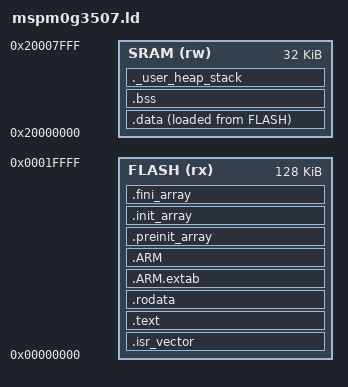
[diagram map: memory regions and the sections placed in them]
/**
 * @file    mspm0g3507.ld
 * @brief   MSPM0G3507链接脚本
 * @version 1.0
 * @date    2024-12-19
 * @author  Bob (架构师)
 * 
 * @note    适用于MSPM0G3507微控制器的链接脚本
 *          Flash: 128KB, SRAM: 32KB
 */

/* 内存布局定义 */
MEMORY
{
    FLASH (rx)  : ORIGIN = 0x00000000, LENGTH = 128K
    SRAM (rw)   : ORIGIN = 0x20000000, LENGTH = 32K
}

/* 栈大小定义 */
_stack_size = 0x1000;  /* 4KB栈空间 */
_heap_size = 0x1000;   /* 4KB堆空间 */

/* 栈顶地址定义 */
_estack = ORIGIN(SRAM) + LENGTH(SRAM);

/* 入口点 */
ENTRY(Reset_Handler)

/* 段定义 */
SECTIONS
{
    /* 中断向量表 */
    .isr_vector :
    {
        . = ALIGN(4);
        KEEP(*(.isr_vector))
        . = ALIGN(4);
    } > FLASH

    /* 程序代码段 */
    .text :
    {
        . = ALIGN(4);
        *(.text)
        *(.text*)
        *(.glue_7)
        *(.glue_7t)
        *(.eh_frame)
        
        KEEP (*(.init))
        KEEP (*(.fini))
        
        . = ALIGN(4);
        _etext = .;
    } > FLASH

    /* 只读数据段 */
    .rodata :
    {
        . = ALIGN(4);
        *(.rodata)
        *(.rodata*)
        . = ALIGN(4);
    } > FLASH

    /* ARM异常处理索引 */
    .ARM.extab :
    {
        *(.ARM.extab* .gnu.linkonce.armextab.*)
    } > FLASH
    
    .ARM :
    {
        __exidx_start = .;
        *(.ARM.exidx*)
        __exidx_end = .;
    } > FLASH

    /* 预初始化数组 */
    .preinit_array :
    {
        PROVIDE_HIDDEN (__preinit_array_start = .);
        KEEP (*(.preinit_array*))
        PROVIDE_HIDDEN (__preinit_array_end = .);
    } > FLASH

    /* 初始化数组 */
    .init_array :
    {
        PROVIDE_HIDDEN (__init_array_start = .);
        KEEP (*(SORT(.init_array.*)))
        KEEP (*(.init_array*))
        PROVIDE_HIDDEN (__init_array_end = .);
    } > FLASH

    /* 析构数组 */
    .fini_array :
    {
        PROVIDE_HIDDEN (__fini_array_start = .);
        KEEP (*(SORT(.fini_array.*)))
        KEEP (*(.fini_array*))
        PROVIDE_HIDDEN (__fini_array_end = .);
    } > FLASH

    /* 初始化数据段 */
    _sidata = LOADADDR(.data);
    .data :
    {
        . = ALIGN(4);
        _sdata = .;
        *(.data)
        *(.data*)
        . = ALIGN(4);
        _edata = .;
    } > SRAM AT > FLASH

    /* 未初始化数据段 */
    .bss :
    {
        . = ALIGN(4);
        _sbss = .;
        __bss_start__ = _sbss;
        *(.bss)
        *(.bss*)
        *(COMMON)
        . = ALIGN(4);
        _ebss = .;
        __bss_end__ = _ebss;
    } > SRAM

    /* 用户堆栈段 */
    ._user_heap_stack :
    {
        . = ALIGN(8);
        PROVIDE ( end = . );
        PROVIDE ( _end = . );
        . = . + _heap_size;
        . = . + _stack_size;
        . = ALIGN(8);
        _sstack = .;
    } > SRAM

    /* 移除调试信息 */
    /DISCARD/ :
    {
        libc.a ( * )
        libm.a ( * )
        libgcc.a ( * )
    }

    .ARM.attributes 0 : { *(.ARM.attributes) }
}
